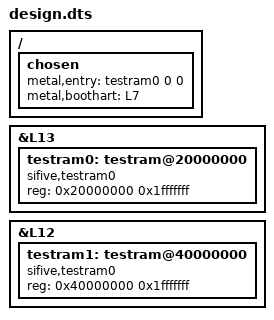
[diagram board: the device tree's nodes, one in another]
/include/ "core.dts"
/ {
	chosen {
		metal,entry = <&testram0 0 0>;
		metal,boothart = <&L7>;
	};
};
&L13 {
	testram0: testram@20000000 {
		compatible = "sifive,testram0";
		reg = <0x20000000 0x1fffffff>;
		reg-names = "mem";
	};
};
&L12 {
	testram1: testram@40000000 {
		compatible = "sifive,testram0";
		reg = <0x40000000 0x1fffffff>;
		reg-names = "mem";
	};
};
